# apollo4l register map
Vendor: Ambiq Micro; Series: Apollo; File version: 1.0
CPU: CM4 r1p0, little endian, MPU, FPU, I-cache, D-cache, VTOR, ITCM, DTCM, 3 interrupt priority bits, 0 interrupts
Registers are 32-bit, read-write, reset 0x0 unless marked. A register's access mark holds for its fields unless they carry their own. Offsets are from the block's base; [hi:lo] are bit positions; lines under a group give offsets from that group.

## CPU — CM4 Complex Registers (Cache, TCM, DAXI)
Base 0x48000000
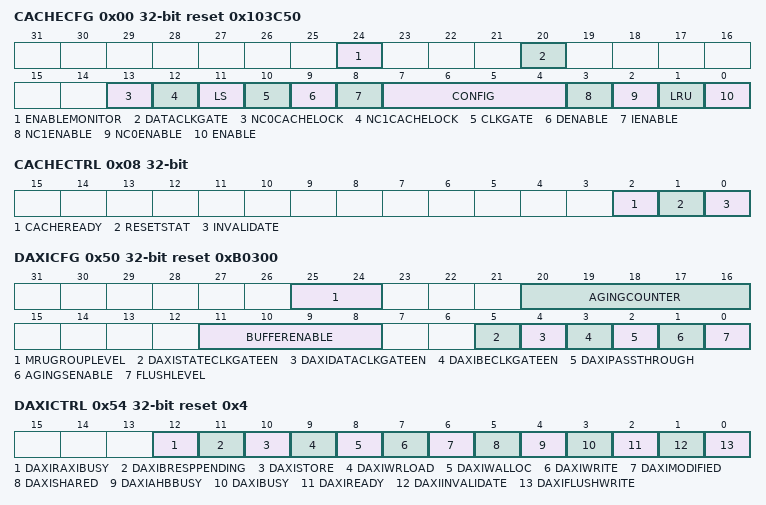
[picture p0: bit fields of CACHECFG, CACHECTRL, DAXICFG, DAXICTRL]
0x00 CACHECFG reset 0x103C50 — CM4 Cache Control
  [24] ENABLEMONITOR — Enable Cache Monitoring Stats. Cache monitoring consumes additional power and should only be enabled when profiling code and counters will increment when this bit is set. Counter values will be retained when this is set to 0, allowing software to enable/disable counting for multiple code segments.
  [20] DATACLKGATE — Enable aggressive clock gating of entire data array. This bit should be set to 1 for optimal power efficiency.
  [13] NC0CACHELOCK — Only valid when Cache Mode D is set. When high sets the mode of the the NC0 region such that all accesse to this region are cached in to the lower half of the cache. When set low then NCR0 is non cacheable.
  [12] NC1CACHELOCK — Only valid when Cache Mode D is set. When high sets the mode of the the NC1 region such that all accesse to this region are cached in to the upper half of the cache. When set low then NCR1 is non cacheable.
  [11] LS — Enable LS (light sleep) of cache RAMs. Software should DISABLE this bit since cache activity is too high to benefit from LS usage.
  [10] CLKGATE — Enable clock gating of cache TAG RAM. Software should enable this bit for optimal power efficiency.
  [9] DENABLE — Enable CM4 Data Caching.
  [8] IENABLE — Enable CM4 Instruction Caching
  [7:4] CONFIG — Sets the cache configuration
    4=W1_128B_512E (Direct mapped, 128-bit linesize, 512 entries (4 SRAMs active)); 5=W2_128B_512E (Two-way set associative, 128-bit linesize, 512 entries (8 SRAMs active)); 8=W1_128B_1024E (Direct mapped, 128-bit linesize, 1024 entries (8 SRAMs active)); 12=W1_128B_2048E (Direct mapped, 128-bit linesize, 2048 entries (4 SRAMs active)); 13=W2_128B_2048E (Two-way set associative, 128-bit linesize, 2048 entries (8 SRAMs active)); 14=W1_128B_4096E (Direct mapped, 128-bit linesize, 4096 entries (8 SRAMs active))
  [3] NC1ENABLE — Enable Non-cacheable region 1. See NCR1 registers to define the region.
  [2] NC0ENABLE — Enable Non-cacheable region 0. See NCR0 registers to define the region.
  [1] LRU — Sets the cache repleacment policy. 0=LRR (least recently replaced), 1=LRU (least recently used). LRR minimizes writes to the TAG SRAM.
  [0] ENABLE — Enables the CM4 cache controller and enables power to the cache SRAMs. The ICACHE_ENABLE and DCACHE_ENABLE should be set to enable caching for each type of access.
0x08 CACHECTRL — Cache Control
  [2] CACHEREADY — Cache Ready Status (enabled and not processing an invalidate operation)
  [1] RESETSTAT — Reset Cache Statistics. When written to a 1, the cache monitor counters will be cleared. The monitor counters can be reset only when the CACHECFG.ENABLE_MONITOR bit is set.
    1=CLEAR (Clear Cache Stats); 0=DEFAULT (default Cache Stats)
  [0] INVALIDATE — Writing a 1 to this bitfield invalidates the CM4 cache contents.
0x10 NCR0START — CM4 Cache Noncachable Region 0 Start
  [28:4] ADDR — Start address for non-cacheable region 0
0x14 NCR0END — CM4 Cache Noncachable Region 0 End
  [28:4] ADDR — End address for non-cacheable region 0
0x18 NCR1START — CM4 Cache Noncachable Region 1 Start
  [28:4] ADDR — Start address for non-cacheable region 1
0x1C NCR1END — CM4 Cache Noncachable Region 1 End
  [28:4] ADDR — End address for non-cacheable region 1
0x50 DAXICFG reset 0xB0300 — DAXI Config
  [25:24] MRUGROUPLEVEL — Sets the MRU group population limit.
    0=MAX (Maximum level for current number of buffers enabled.); 1=ONELESSTHANMAX (One less than maximum level or zero for current number of buffers enabled.); 2=TWOLESSTHANMAX (Two less than maximum level or zero for current number of buffers enabled.); 3=THREELESSTHANMAX (Three less than maximum level or zero for current number of buffers enabled.)
  [20:16] AGINGCOUNTER — Specifies the relative time that DAXI buffers may remain unused before being flushed. Counter is based on CPU clock cycles and buffers will generally be flushed in 1-2 AGINGCOUNTER timesteps.
    0=ONE (One step per age); 1=TWO (Two steps per age); 2=FOUR (Four steps per age); 3=EIGHT (EIGHT steps per age); 4=SIXTEEN (Sixteen steps per age); 5=THIRTYTWO (Thirty-two steps per age); 6=SIXTYFOUR (64 steps per age); 7=ONEHUNDREDTWENTYEIGHT (One hundred twenty-eight steps per age); 8=TWOHUNDEREDFIFTYSIX (Two hundred fifty-six steps per age); 9=FIVEHUNDREDTWELVE (Five hundred twelve steps per age); 10=ONEK (One thousand twenty-four steps per age); 11=TWOK (Two thousand forty-eight steps per age); 12=FOURK (Four thousand ninety-six steps per age); 13=EIGHTK (Eight thousand one hundred ninety-two steps per age); 14=SIXTEENK (Sixteen thousand three hundred eighty-four steps per age); 15=THIRTYTWOK (Thirty-two thousand seven hundred sixty-eight steps per age); 16=SIXTYFOURK (Sixty-fix thousand five hundred thirty-six steps per age)
  [11:8] BUFFERENABLE — Enables DAXI buffers
    0=ONE (One buffer mode enabled.); 1=TWO (Two buffers enabled.); 2=THREE (Three buffers enabled.); 3=FOUR (Four buffers enabled.); 4=FIVE (Five buffers enabled.); 5=SIX (Six buffers enabled.); 6=SEVEN (Seven buffers enabled.); 7=EIGHT (Eight buffers enabled.); 8=THIRTEEN (Eight buffers enabled.); 9=FOURTEEN (Eight buffers enabled.); 10=FIFTEEN (Eight buffers enabled.); 11=SIXTEEN (Eight buffers enabled.); 12=TWENTYNINE (Twenty-nine buffers enabled.); 13=THIRTY (Thirty buffers enabled.); 14=THIRTYONE (Thirty-one buffers enabled.); 15=THIRTYTWO (Thirty-two buffers enabled.)
  [5] DAXISTATECLKGATEEN — Enables clock gating of DAXI state.
    0=EN (Enable clock gating of DAXI state.); 1=DIS (Disable clock gating of DAXI state.)
  [4] DAXIDATACLKGATEEN — Enables clock gating of DAXI line buffer data.
    0=EN (Enable clock gating of DAXI line buffer data.); 1=DIS (Disable clock gating of DAXI line buffer data.)
  [3] DAXIBECLKGATEEN — Enables clock gating of DAXI line buffer byte enables.
    0=EN (Enable clock gating of DAXI line buffer byte enables.); 1=DIS (Disable clock gating of DAXI line buffer byte enables.)
  [2] DAXIPASSTHROUGH — Passes requests through DAXI logic, disables caching lines in the DAXI line buffers.
    0=DIS (Disable pass through mode, caching lines in DAXI enabled.); 1=EN (Enable pass through mode, caching lines in DAXI disabled.)
  [1] AGINGSENABLE — Enables flushing out shared lines using the aging mechanism.
    0=DIS (Flushing out shared entries using aging mechanism disabled.); 1=EN (Flushing out shared entries using aging mechanism enabled.)
  [0] FLUSHLEVEL — Level of free buffers to flush out dirty buffers.
    0=TWO (Flush out dirty buffers if 3 or more ane enabled and less than two are free or if 2 are enabled and none are free.); 1=THREE (Flush out dirty buffers if 3 or more are enabled less than three are free or if 2 are enabled and less then two are free.)
0x54 DAXICTRL reset 0x4 — DAXI Control
  [12] DAXIRAXIBUSY — DAXI status indicating the DAXI RAXI interface is busy.
  [11] DAXIBRESPPENDING — DAXI status indicating at least one AXI B repsonse for a store is pending.
  [10] DAXISTORE — DAXI status indicating at least one buffer has outstanding store waiting to complete.
  [9] DAXIWRLOAD — DAXI status indicating at least one partially written buffer is waiting for load to convert to modified.
  [8] DAXIWALLOC — DAXI status indicating at least one write allocation is waiting for prior store to complete.
  [7] DAXIWRITE — DAXI status indicating at least one partially written buffer has modified data.
  [6] DAXIMODIFIED — DAXI status indicating at least one full buffer has modified data.
  [5] DAXISHARED — DAXI status indicating at least one full buffer is shared.
  [4] DAXIAHBBUSY — DAXI status indicating DAXI AHB interface is busy.
  [3] DAXIBUSY — DAXI status indicating DAXI is busy.
  [2] DAXIREADY — DAXI Ready Status (enabled and not processing a flush of WRITE or MODIFIED buffers)
  [1] DAXIINVALIDATE — Writing a 1 to this bitfield invalidates any SHARED data buffers (S->I).
  [0] DAXIFLUSHWRITE — Writing a 1 to this bitfield forces a flush of WRITE (W->I) or MODIFIED buffers (M->S).
0x80 ICODEFAULTADDR — ICODE bus address which was present when a bus fault occurred.
  [31:0] ICODEFAULTADDR — The ICODE bus address observed when a Bus Fault occurred. Once an address is captured in this field, it is held until the corresponding Fault Observed bit is cleared in the FAULTSTATUS register.
0x84 DCODEFAULTADDR — DCODE bus address which was present when a bus fault occurred.
  [31:0] DCODEFAULTADDR — The DCODE bus address observed when a Bus Fault occurred. Once an address is captured in this field, it is held until the corresponding Fault Observed bit is cleared in the FAULTSTATUS register.
0x88 SYSFAULTADDR — System bus address which was present when a bus fault occurred.
  [31:0] SYSFAULTADDR — SYS bus address observed when a Bus Fault occurred. Once an address is captured in this field, it is held until the corresponding Fault Observed bit is cleared in the FAULTSTATUS register.
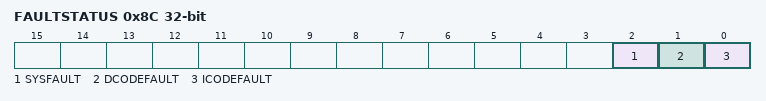
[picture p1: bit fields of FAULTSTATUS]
0x8C FAULTSTATUS — Reflects the status of the bus decoders' fault detection. Any write to this register will clear all of the status bits within the register.
  [2] SYSFAULT — SYS Bus Decoder Fault Detected bit. When set, a fault has been detected, and the SYSFAULTADDR register will contain the bus address which generated the fault.
    0=NOFAULT (No bus fault has been detected.); 1=FAULT (Bus fault detected.)
  [1] DCODEFAULT — DCODE Bus Decoder Fault Detected bit. When set, a fault has been detected, and the DCODEFAULTADDR register will contain the bus address which generated the fault.
    0=NOFAULT (No DCODE fault has been detected.); 1=FAULT (DCODE fault detected.)
  [0] ICODEFAULT — The ICODE Bus Decoder Fault Detected bit. When set, a fault has been detected, and the ICODEFAULTADDR register will contain the bus address which generated the fault.
    0=NOFAULT (No ICODE fault has been detected.); 1=FAULT (ICODE fault detected.)
0x90 FAULTCAPTUREEN — Enable the fault capture registers
  [0] FAULTCAPTUREEN — Fault Capture Enable field. When set, the Fault Capture monitors are enabled and addresses which generate a hard fault are captured into the FAULTADDR registers.
    0=DIS (Disable fault capture.); 1=EN (Enable fault capture.)
0xC0 INTEN — Set bits in this register to allow this module to generate the corresponding interrupt.
  [0] AXIWERROR — AXI Write Error Occurred
0xC4 INTSTAT — Read bits from this register to discover the cause of a recent interrupt.
  [0] AXIWERROR — AXI Write Error Occurred
0xC8 INTCLR — Write a 1 to a bit in this register to clear the interrupt status associated with that bit.
  [0] AXIWERROR — AXI Write Error Occurred
0xCC INTSET — Write a 1 to a bit in this register to instantly generate an interrupt from this module. (Generally used for testing purposes).
  [0] AXIWERROR — AXI Write Error Occurred
0xD0 WRITEERRADDR — DAXI Write Error Address
  [31:0] WERRADDR — This address will be approximate since multiple write transactions might be in flight at any given time. However, it should be accurate when debugging/single-stepping
0x100 DMON0 — Data Cache Total Accesses
  [31:0] DACCESS — Total accesses to data cache. All performance metrics should be relative to the number of accesses performed.
0x104 DMON1 — Data Cache Tag Lookups
  [31:0] DLOOKUP — Total tag lookups from data cache.
0x108 DMON2 — Data Cache Hits
  [31:0] DHIT — Cache hits from lookup operations.
0x10C DMON3 — Data Cache Line Hits
  [31:0] DLINE — Cache hits from line cache
0x110 IMON0 — Instruction Cache Total Accesses
  [31:0] IACCESS — Total accesses to Instruction cache
0x114 IMON1 — Instruction Cache Tag Lookups
  [31:0] ILOOKUP — Total tag lookups from Instruction cache
0x118 IMON2 — Instruction Cache Hits
  [31:0] IHIT — Cache hits from lookup operations
0x11C IMON3 — Instruction Cache Line Hits
  [31:0] ILINE — Cache hits from line cache

## Notices in the file
Copyright (C) 2012-2014 ARM Limited. All rights reserved.
Purpose: System Viewer Description (SVD) Example (Schema Version 1.1)
This is a description of a none-existent and incomplete device
for demonstration purposes only.
Redistribution and use in source and binary forms, with or without
modification, are permitted provided that the following conditions are met:
- Redistributions of source code must retain the above copyright
notice, this list of conditions and the following disclaimer.
- Redistributions in binary form must reproduce the above copyright
notice, this list of conditions and the following disclaimer in the
documentation and/or other materials provided with the distribution.
- Neither the name of ARM nor the names of its contributors may be used
to endorse or promote products derived from this software without
specific prior written permission.
THIS SOFTWARE IS PROVIDED BY THE COPYRIGHT HOLDERS AND CONTRIBUTORS "AS IS"
AND ANY EXPRESS OR IMPLIED WARRANTIES, INCLUDING, BUT NOT LIMITED TO, THE
IMPLIED WARRANTIES OF MERCHANTABILITY AND FITNESS FOR A PARTICULAR PURPOSE
ARE DISCLAIMED. IN NO EVENT SHALL COPYRIGHT HOLDERS AND CONTRIBUTORS BE
LIABLE FOR ANY DIRECT, INDIRECT, INCIDENTAL, SPECIAL, EXEMPLARY, OR
CONSEQUENTIAL DAMAGES (INCLUDING, BUT NOT LIMITED TO, PROCUREMENT OF
SUBSTITUTE GOODS OR SERVICES; LOSS OF USE, DATA, OR PROFITS; OR BUSINESS
INTERRUPTION) HOWEVER CAUSED AND ON ANY THEORY OF LIABILITY, WHETHER IN
CONTRACT, STRICT LIABILITY, OR TORT (INCLUDING NEGLIGENCE OR OTHERWISE)
ARISING IN ANY WAY OUT OF THE USE OF THIS SOFTWARE, EVEN IF ADVISED OF THE
POSSIBILITY OF SUCH DAMAGE.
